# NAVSS0_MAILBOX0_REGS0 register map
Vendor: Texas Instruments
Peripheral module from a debugger description file (folder J7VCL).
Registers are 32-bit, read-write, reset 0x0 unless marked. A register's access mark holds for its fields unless they carry their own. Offsets are as the file gives them; lines under a group give offsets from that group; [hi:lo] are bit positions; {n}, {i} and the like mark numbered series; 'fields as' and 'values as' point back to an identical list; <NAME> marks a mode.

## NAVSS0_MAILBOX0_REGS0
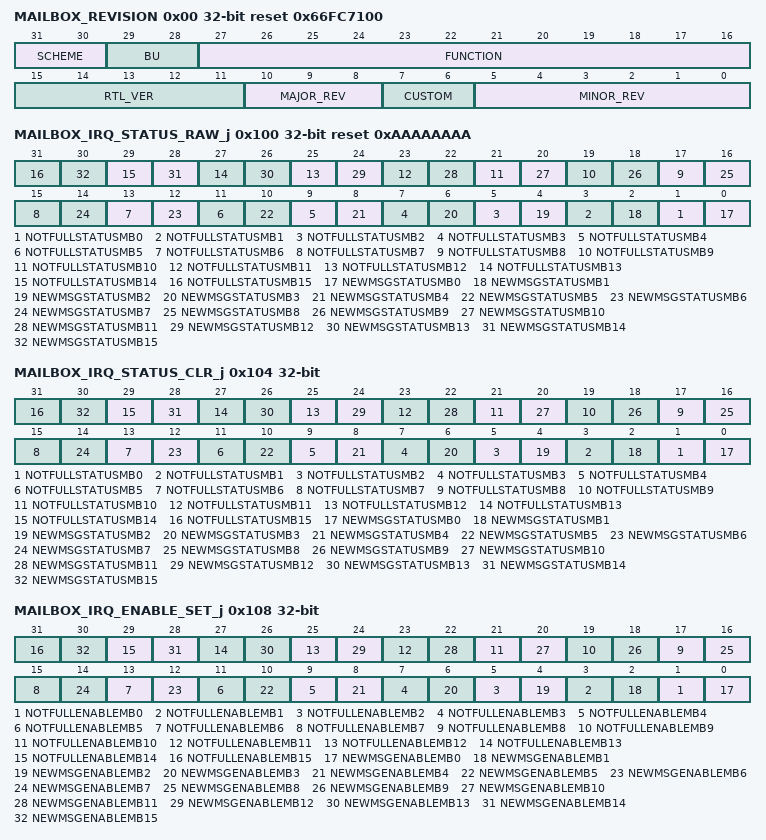
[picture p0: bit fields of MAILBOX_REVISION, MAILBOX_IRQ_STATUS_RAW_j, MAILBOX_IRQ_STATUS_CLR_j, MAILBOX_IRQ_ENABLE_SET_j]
0x00 MAILBOX_REVISION ro reset 0x66FC7100 — This is the standard TI peripheral ID register that exists at address 0 in the peripheral space Reset = 66FC 7100h
  [31:30] SCHEME — Used to distinguish which ID numbering scheme is used.
  [29:28] BU — BU identifier
  [27:16] FUNCTION — Module family.
  [15:11] RTL_VER — RTL version. R of X.Y.R.Z
  [10:8] MAJOR_REV — Major revision. X of X.Y.R.Z
  [7:6] CUSTOM — Special version number
  [5:0] MINOR_REV — Minor revision. Y of X.Y.R.Z
0x10 MAILBOX_SYSCONFIG — This register contains parameters to control the whole Mailbox system. Provided for backwards compatibility with OMAP Mailbox. Only contains the soft reset.
  [0] SOFT_RESET — Module Software Reset The bit is automatically reset by the hardware. During reads, it always returns 0. It has the same effect as the hardware reset. Writing a 0 has no effect. Writing a 1 will start a soft reset sequence and empty all the mailboxes
0x40 MAILBOX_MESSAGE_y — The message register stores the next to-be-read message of the mailbox. Read: Reads the next available message. Write: Add a message to this mailbox queue. Offset = 40h + (y * 4h); where y = 0h to Fh
  [31:0] VALUE — Message in Mailbox y
0x80 MAILBOX_FIFO_STATUS_y ro — The FIFO status register has the status of the Mailbox y FIFO Offset = 80h + (y * 4h); where y = 0h to Fh
  [0] FULL — Full flag for Mailbox y
0xC0 MAILBOX_MSG_STATUS_y ro — The message status register has the status of the messages in Mailbox y Offset = C0h + (y * 4h); where y = 0h to Fh
  [2:0] NUM_MESSAGES — Number of messages in Mailbox y
0x100 MAILBOX_IRQ_STATUS_RAW_j reset 0xAAAAAAAA — The interrupt status register has the status for each event that may be responsible for the generation of an interrupt to the corresponding user . Software may also write 1 to a given bit to set this bit to test interrupt generation. It will activate the status bit for two cycles. This may still be masked, however. Write 0 has no effect. Offset = 100h + (j * 10h); where j = 0h to 3h
  [2n+1] NOTFULLSTATUSMB{n} (n=0..15) — 1 if Mailbox {n} is not full
  [2n] NEWMSGSTATUSMB{n} (n=0..15) — 1 if there are messages present in Mailbox {n}
0x104 MAILBOX_IRQ_STATUS_CLR_j — The interrupt status register has the status for each event that may be responsible for the generation of an interrupt to the corresponding user combined with the corresponding MASK information. Software may also write 1 to a given bit to clear this bit. However, if the hardware still has pending, enabled events, the interrupt will fire again in two cycles. Write 0 has no effect. Offset = 104h + (j * 10h); where j = 0h to 3h
  [2n+1] NOTFULLSTATUSMB{n} (n=0..15) — 1 if Mailbox {n} is not full and this interrupt bit is enabled
  [2n] NEWMSGSTATUSMB{n} (n=0..15) — 1 if there are messages present in Mailbox {n} and this interrupt bit is enabled
0x108 MAILBOX_IRQ_ENABLE_SET_j — The interrupt enable register allows software to mask/unmask the module internal source of interrupt for the user j. Read value is the current enable bits for each interrupt source. Write 1 to a bit enables an interrupt source. Write 0 has no effect. Offset = 108h + (j * 10h); where j = 0h to 3h
  [2n+1] NOTFULLENABLEMB{n} (n=0..15) — Read value is current enable state for this interrupt. Write 1 enables the interrupt. Write 0 no action.
  [2n] NEWMSGENABLEMB{n} (n=0..15) — Read value is current enable state for this interrupt. Write 1 enables the interrupt. Write 0 no action.
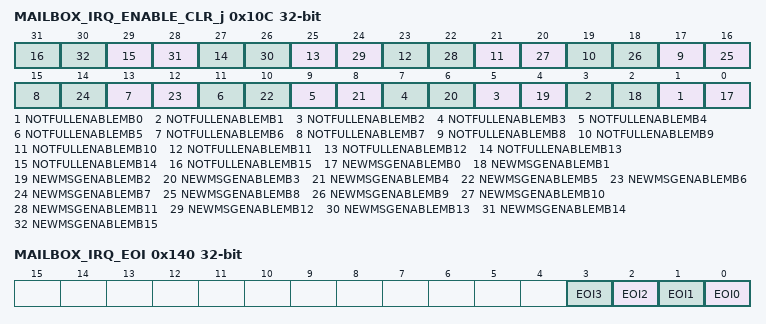
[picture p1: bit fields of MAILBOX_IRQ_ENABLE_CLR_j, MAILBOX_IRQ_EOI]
0x10C MAILBOX_IRQ_ENABLE_CLR_j — The interrupt enable register allows software to mask/unmask the module internal source of interrupt for the user j. Read value is the current enable bits for each interrupt sourc. Write 1 to a bit disables an interrupt source. Write 0 has no effect. Offset = 10Ch + (j * 10h); where j = 0h to 3h
  [2n+1] NOTFULLENABLEMB{n} (n=0..15) — Read value is current enable state for this interrupt. Write 1 disables the interrupt. Write 0 no action.
  [2n] NEWMSGENABLEMB{n} (n=0..15) — Read value is current enable state for this interrupt. Write 1 disables the interrupt. Write 0 no action.
0x140 MAILBOX_IRQ_EOI wo — This is the EOI register with which the software is enabled to do the interrupt clearance. The EOI register is used to re-trigger the pulse interrupt signal to ensure that any nested interrupt events are serviced. The software interrupt handler must write to the EOI register at the end of the current interrupt processing routine, so that new events can re-trigger the pulse interrupt signal again. For level interrupt signals the EOI register is not functional and must not be used.
  [n] EOI{n} (n=0..3) — Software EOI signal for the user {n} interrupt
